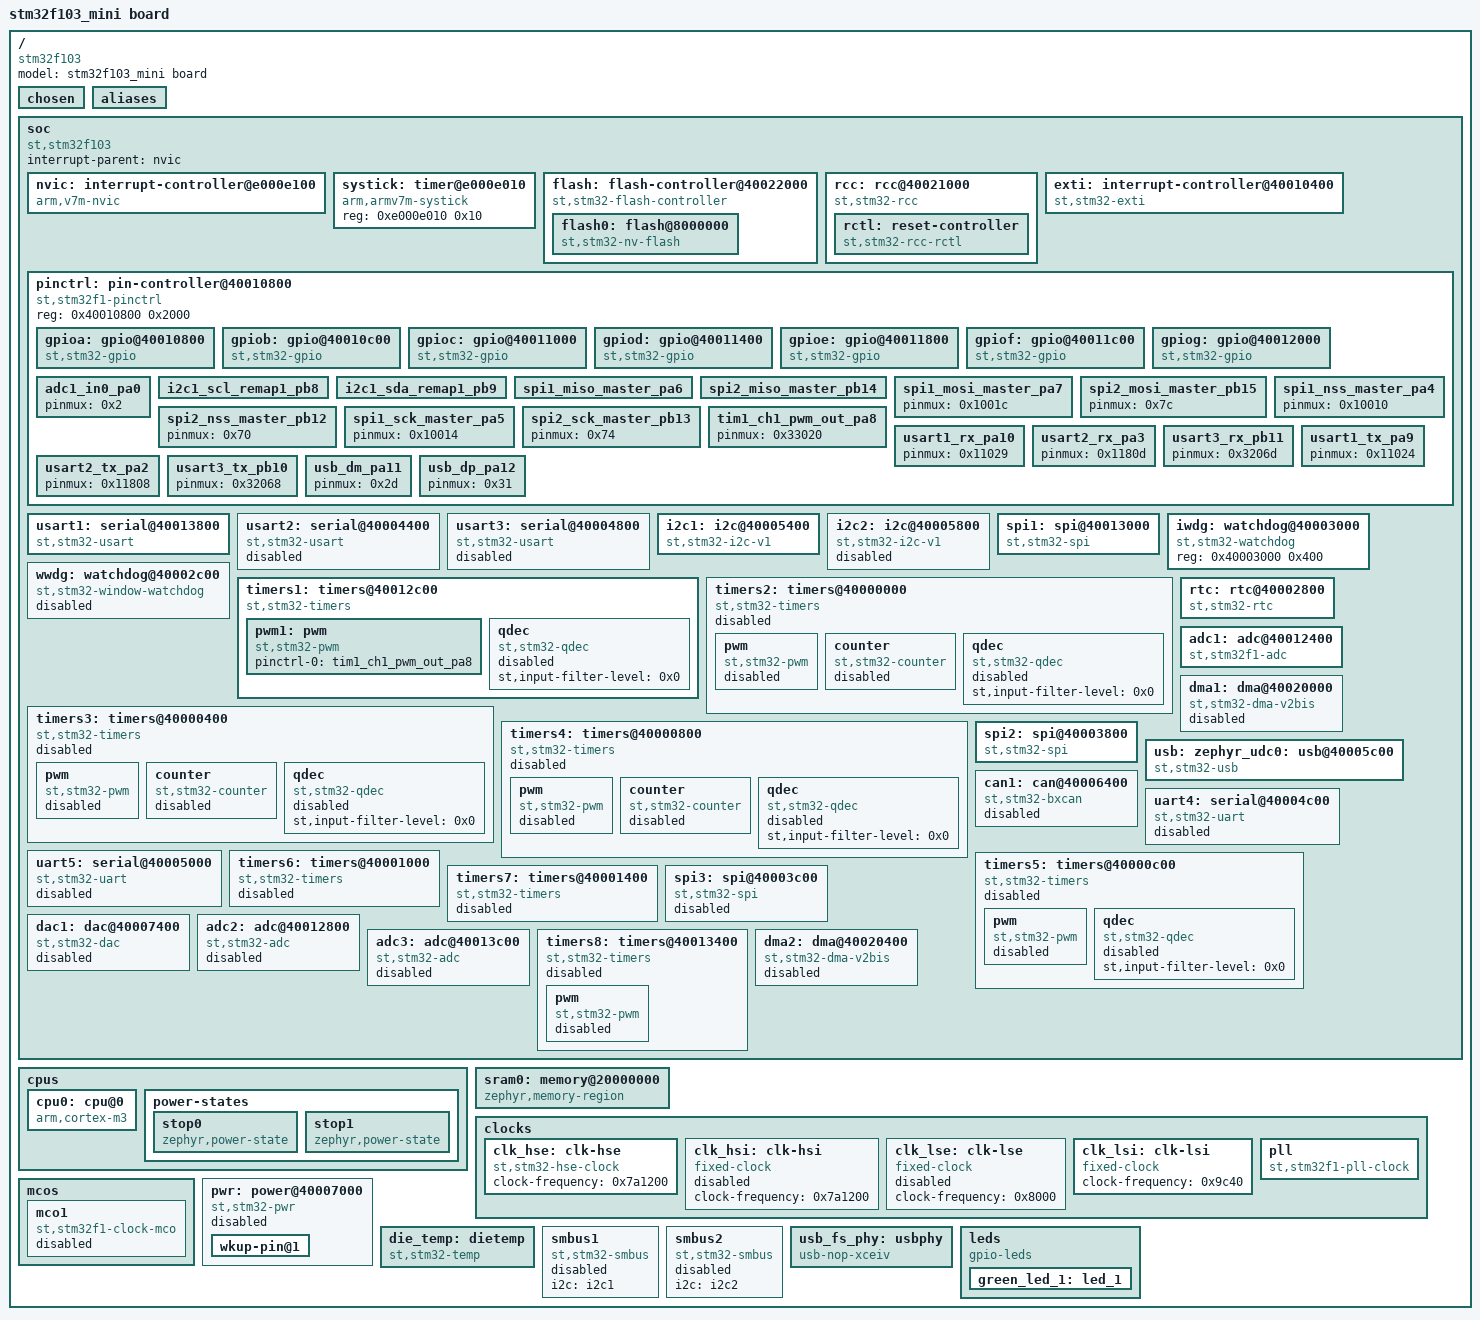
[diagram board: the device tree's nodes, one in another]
/dts-v1/;

/* node '/' defined in zephyr/dts/common/skeleton.dtsi:9 */
/ {
	#address-cells = < 0x1 >;       /* in zephyr/dts/common/skeleton.dtsi:10 */
	#size-cells = < 0x1 >;          /* in zephyr/dts/common/skeleton.dtsi:11 */
	model = "stm32f103_mini board"; /* in zephyr/boards/others/stm32f103_mini/stm32f103_mini.dts:12 */
	compatible = "stm32f103";       /* in zephyr/boards/others/stm32f103_mini/stm32f103_mini.dts:13 */

	/* node '/chosen' defined in zephyr/dts/common/skeleton.dtsi:13 */
	chosen {
		zephyr,flash-controller = &flash;  /* in zephyr/dts/arm/st/f1/stm32f1.dtsi:25 */
		zephyr,cortex-m-idle-timer = &rtc; /* in zephyr/dts/arm/st/f1/stm32f1.dtsi:26 */
		zephyr,console = &usart1;          /* in zephyr/boards/others/stm32f103_mini/stm32f103_mini.dts:16 */
		zephyr,shell-uart = &usart1;       /* in zephyr/boards/others/stm32f103_mini/stm32f103_mini.dts:17 */
		zephyr,sram = &sram0;              /* in zephyr/boards/others/stm32f103_mini/stm32f103_mini.dts:18 */
		zephyr,flash = &flash0;            /* in zephyr/boards/others/stm32f103_mini/stm32f103_mini.dts:19 */
	};

	/* node '/aliases' defined in zephyr/dts/common/skeleton.dtsi:15 */
	aliases {
		led0 = &green_led_1;   /* in zephyr/boards/others/stm32f103_mini/stm32f103_mini.dts:32 */
		watchdog0 = &iwdg;     /* in zephyr/boards/others/stm32f103_mini/stm32f103_mini.dts:33 */
		die-temp0 = &die_temp; /* in zephyr/boards/others/stm32f103_mini/stm32f103_mini.dts:34 */
	};

	/* node '/soc' defined in zephyr/dts/arm/armv7-m.dtsi:6 */
	soc {
		#address-cells = < 0x1 >;     /* in zephyr/dts/arm/armv7-m.dtsi:7 */
		#size-cells = < 0x1 >;        /* in zephyr/dts/arm/armv7-m.dtsi:8 */
		interrupt-parent = < &nvic >; /* in zephyr/dts/arm/armv7-m.dtsi:10 */
		ranges;                       /* in zephyr/dts/arm/armv7-m.dtsi:11 */
		compatible = "st,stm32f103",
		             "st,stm32f1",
		             "simple-bus";    /* in zephyr/dts/arm/st/f1/stm32f103X8.dtsi:15 */

		/* node '/soc/interrupt-controller@e000e100' defined in zephyr/dts/arm/armv7-m.dtsi:13 */
		nvic: interrupt-controller@e000e100 {
			#address-cells = < 0x1 >;            /* in zephyr/dts/arm/armv7-m.dtsi:14 */
			compatible = "arm,v7m-nvic";         /* in zephyr/dts/arm/armv7-m.dtsi:15 */
			reg = < 0xe000e100 0xc00 >;          /* in zephyr/dts/arm/armv7-m.dtsi:16 */
			interrupt-controller;                /* in zephyr/dts/arm/armv7-m.dtsi:17 */
			#interrupt-cells = < 0x2 >;          /* in zephyr/dts/arm/armv7-m.dtsi:18 */
			arm,num-irq-priority-bits = < 0x4 >; /* in zephyr/dts/arm/st/f1/stm32f1.dtsi:461 */
			phandle = < 0x1 >;                   /* in zephyr/dts/arm/armv7-m.dtsi:10 */
		};

		/* node '/soc/timer@e000e010' defined in zephyr/dts/arm/armv7-m.dtsi:21 */
		systick: timer@e000e010 {
			compatible = "arm,armv7m-systick"; /* in zephyr/dts/arm/armv7-m.dtsi:22 */
			reg = < 0xe000e010 0x10 >;         /* in zephyr/dts/arm/armv7-m.dtsi:23 */
		};

		/* node '/soc/flash-controller@40022000' defined in zephyr/dts/arm/st/f1/stm32f1.dtsi:107 */
		flash: flash-controller@40022000 {
			compatible = "st,stm32-flash-controller",
			             "st,stm32f1-flash-controller"; /* in zephyr/dts/arm/st/f1/stm32f1.dtsi:108 */
			reg = < 0x40022000 0x400 >;                 /* in zephyr/dts/arm/st/f1/stm32f1.dtsi:109 */
			interrupts = < 0x3 0x0 >;                   /* in zephyr/dts/arm/st/f1/stm32f1.dtsi:110 */
			clocks = < &rcc 0x14 0x10 >;                /* in zephyr/dts/arm/st/f1/stm32f1.dtsi:111 */
			#address-cells = < 0x1 >;                   /* in zephyr/dts/arm/st/f1/stm32f1.dtsi:113 */
			#size-cells = < 0x1 >;                      /* in zephyr/dts/arm/st/f1/stm32f1.dtsi:114 */

			/* node '/soc/flash-controller@40022000/flash@8000000' defined in zephyr/dts/arm/st/f1/stm32f1.dtsi:116 */
			flash0: flash@8000000 {
				compatible = "st,stm32-nv-flash",
				             "soc-nv-flash";      /* in zephyr/dts/arm/st/f1/stm32f1.dtsi:117 */
				write-block-size = < 0x2 >;       /* in zephyr/dts/arm/st/f1/stm32f1.dtsi:119 */
				max-erase-time = < 0x28 >;        /* in zephyr/dts/arm/st/f1/stm32f1.dtsi:121 */
				reg = < 0x8000000 0x40000 >;      /* in zephyr/dts/arm/st/f1/stm32f103Xc.dtsi:21 */
				erase-block-size = < 0x800 >;     /* in zephyr/dts/arm/st/f1/stm32f103Xc.dtsi:22 */
			};
		};

		/* node '/soc/rcc@40021000' defined in zephyr/dts/arm/st/f1/stm32f1.dtsi:125 */
		rcc: rcc@40021000 {
			compatible = "st,stm32-rcc";     /* in zephyr/dts/arm/st/f1/stm32f1.dtsi:126 */
			#clock-cells = < 0x2 >;          /* in zephyr/dts/arm/st/f1/stm32f1.dtsi:127 */
			reg = < 0x40021000 0x400 >;      /* in zephyr/dts/arm/st/f1/stm32f1.dtsi:128 */
			clocks = < &pll >;               /* in zephyr/boards/others/stm32f103_mini/stm32f103_mini.dts:54 */
			clock-frequency = < 0x44aa200 >; /* in zephyr/boards/others/stm32f103_mini/stm32f103_mini.dts:55 */
			ahb-prescaler = < 0x1 >;         /* in zephyr/boards/others/stm32f103_mini/stm32f103_mini.dts:56 */
			apb1-prescaler = < 0x2 >;        /* in zephyr/boards/others/stm32f103_mini/stm32f103_mini.dts:57 */
			apb2-prescaler = < 0x1 >;        /* in zephyr/boards/others/stm32f103_mini/stm32f103_mini.dts:58 */
			phandle = < 0x2 >;               /* in zephyr/dts/arm/st/f1/stm32f1.dtsi:111 */

			/* node '/soc/rcc@40021000/reset-controller' defined in zephyr/dts/arm/st/f1/stm32f1.dtsi:130 */
			rctl: reset-controller {
				compatible = "st,stm32-rcc-rctl"; /* in zephyr/dts/arm/st/f1/stm32f1.dtsi:131 */
				#reset-cells = < 0x1 >;           /* in zephyr/dts/arm/st/f1/stm32f1.dtsi:132 */
				phandle = < 0x4 >;                /* in zephyr/dts/arm/st/f1/stm32f1.dtsi:202 */
			};
		};

		/* node '/soc/interrupt-controller@40010400' defined in zephyr/dts/arm/st/f1/stm32f1.dtsi:136 */
		exti: interrupt-controller@40010400 {
			compatible = "st,stm32-exti";  /* in zephyr/dts/arm/st/f1/stm32f1.dtsi:137 */
			interrupt-controller;          /* in zephyr/dts/arm/st/f1/stm32f1.dtsi:138 */
			#interrupt-cells = < 0x1 >;    /* in zephyr/dts/arm/st/f1/stm32f1.dtsi:139 */
			#address-cells = < 0x0 >;      /* in zephyr/dts/arm/st/f1/stm32f1.dtsi:140 */
			reg = < 0x40010400 0x400 >;    /* in zephyr/dts/arm/st/f1/stm32f1.dtsi:141 */
			num-lines = < 0x20 >;          /* in zephyr/dts/arm/st/f1/stm32f1.dtsi:142 */
			interrupts = < 0x6 0x0 >,
			             < 0x7 0x0 >,
			             < 0x8 0x0 >,
			             < 0x9 0x0 >,
			             < 0xa 0x0 >,
			             < 0x17 0x0 >,
			             < 0x28 0x0 >;     /* in zephyr/dts/arm/st/f1/stm32f1.dtsi:143 */
			interrupt-names = "line0",
			                  "line1",
			                  "line2",
			                  "line3",
			                  "line4",
			                  "line5-9",
			                  "line10-15"; /* in zephyr/dts/arm/st/f1/stm32f1.dtsi:145 */
			line-ranges = < 0x0 0x1 >,
			              < 0x1 0x1 >,
			              < 0x2 0x1 >,
			              < 0x3 0x1 >,
			              < 0x4 0x1 >,
			              < 0x5 0x5 >,
			              < 0xa 0x6 >;     /* in zephyr/dts/arm/st/f1/stm32f1.dtsi:147 */
		};

		/* node '/soc/pin-controller@40010800' defined in zephyr/dts/arm/st/f1/stm32f1.dtsi:151 */
		pinctrl: pin-controller@40010800 {
			compatible = "st,stm32f1-pinctrl"; /* in zephyr/dts/arm/st/f1/stm32f1.dtsi:152 */
			#address-cells = < 0x1 >;          /* in zephyr/dts/arm/st/f1/stm32f1.dtsi:153 */
			#size-cells = < 0x1 >;             /* in zephyr/dts/arm/st/f1/stm32f1.dtsi:154 */
			reg = < 0x40010800 0x2000 >;       /* in zephyr/dts/arm/st/f1/stm32f103Xc.dtsi:111 */

			/* node '/soc/pin-controller@40010800/gpio@40010800' defined in zephyr/dts/arm/st/f1/stm32f1.dtsi:157 */
			gpioa: gpio@40010800 {
				compatible = "st,stm32-gpio"; /* in zephyr/dts/arm/st/f1/stm32f1.dtsi:158 */
				gpio-controller;              /* in zephyr/dts/arm/st/f1/stm32f1.dtsi:159 */
				#gpio-cells = < 0x2 >;        /* in zephyr/dts/arm/st/f1/stm32f1.dtsi:160 */
				reg = < 0x40010800 0x400 >;   /* in zephyr/dts/arm/st/f1/stm32f1.dtsi:161 */
				clocks = < &rcc 0x18 0x4 >;   /* in zephyr/dts/arm/st/f1/stm32f1.dtsi:162 */
				phandle = < 0x1d >;           /* in zephyr/dts/arm/st/f1/stm32f1.dtsi:430 */
			};

			/* node '/soc/pin-controller@40010800/gpio@40010c00' defined in zephyr/dts/arm/st/f1/stm32f1.dtsi:165 */
			gpiob: gpio@40010c00 {
				compatible = "st,stm32-gpio"; /* in zephyr/dts/arm/st/f1/stm32f1.dtsi:166 */
				gpio-controller;              /* in zephyr/dts/arm/st/f1/stm32f1.dtsi:167 */
				#gpio-cells = < 0x2 >;        /* in zephyr/dts/arm/st/f1/stm32f1.dtsi:168 */
				reg = < 0x40010c00 0x400 >;   /* in zephyr/dts/arm/st/f1/stm32f1.dtsi:169 */
				clocks = < &rcc 0x18 0x8 >;   /* in zephyr/dts/arm/st/f1/stm32f1.dtsi:170 */
			};

			/* node '/soc/pin-controller@40010800/gpio@40011000' defined in zephyr/dts/arm/st/f1/stm32f1.dtsi:173 */
			gpioc: gpio@40011000 {
				compatible = "st,stm32-gpio"; /* in zephyr/dts/arm/st/f1/stm32f1.dtsi:174 */
				gpio-controller;              /* in zephyr/dts/arm/st/f1/stm32f1.dtsi:175 */
				#gpio-cells = < 0x2 >;        /* in zephyr/dts/arm/st/f1/stm32f1.dtsi:176 */
				reg = < 0x40011000 0x400 >;   /* in zephyr/dts/arm/st/f1/stm32f1.dtsi:177 */
				clocks = < &rcc 0x18 0x10 >;  /* in zephyr/dts/arm/st/f1/stm32f1.dtsi:178 */
				phandle = < 0x21 >;           /* in zephyr/boards/others/stm32f103_mini/stm32f103_mini.dts:26 */
			};

			/* node '/soc/pin-controller@40010800/gpio@40011400' defined in zephyr/dts/arm/st/f1/stm32f1.dtsi:181 */
			gpiod: gpio@40011400 {
				compatible = "st,stm32-gpio"; /* in zephyr/dts/arm/st/f1/stm32f1.dtsi:182 */
				gpio-controller;              /* in zephyr/dts/arm/st/f1/stm32f1.dtsi:183 */
				#gpio-cells = < 0x2 >;        /* in zephyr/dts/arm/st/f1/stm32f1.dtsi:184 */
				reg = < 0x40011400 0x400 >;   /* in zephyr/dts/arm/st/f1/stm32f1.dtsi:185 */
				clocks = < &rcc 0x18 0x20 >;  /* in zephyr/dts/arm/st/f1/stm32f1.dtsi:186 */
			};

			/* node '/soc/pin-controller@40010800/gpio@40011800' defined in zephyr/dts/arm/st/f1/stm32f1.dtsi:189 */
			gpioe: gpio@40011800 {
				compatible = "st,stm32-gpio"; /* in zephyr/dts/arm/st/f1/stm32f1.dtsi:190 */
				gpio-controller;              /* in zephyr/dts/arm/st/f1/stm32f1.dtsi:191 */
				#gpio-cells = < 0x2 >;        /* in zephyr/dts/arm/st/f1/stm32f1.dtsi:192 */
				reg = < 0x40011800 0x400 >;   /* in zephyr/dts/arm/st/f1/stm32f1.dtsi:193 */
				clocks = < &rcc 0x18 0x40 >;  /* in zephyr/dts/arm/st/f1/stm32f1.dtsi:194 */
			};

			/* node '/soc/pin-controller@40010800/gpio@40011c00' defined in zephyr/dts/arm/st/f1/stm32f103Xc.dtsi:113 */
			gpiof: gpio@40011c00 {
				compatible = "st,stm32-gpio"; /* in zephyr/dts/arm/st/f1/stm32f103Xc.dtsi:114 */
				gpio-controller;              /* in zephyr/dts/arm/st/f1/stm32f103Xc.dtsi:115 */
				#gpio-cells = < 0x2 >;        /* in zephyr/dts/arm/st/f1/stm32f103Xc.dtsi:116 */
				reg = < 0x40011c00 0x400 >;   /* in zephyr/dts/arm/st/f1/stm32f103Xc.dtsi:117 */
				clocks = < &rcc 0x18 0x80 >;  /* in zephyr/dts/arm/st/f1/stm32f103Xc.dtsi:118 */
			};

			/* node '/soc/pin-controller@40010800/gpio@40012000' defined in zephyr/dts/arm/st/f1/stm32f103Xc.dtsi:121 */
			gpiog: gpio@40012000 {
				compatible = "st,stm32-gpio"; /* in zephyr/dts/arm/st/f1/stm32f103Xc.dtsi:122 */
				gpio-controller;              /* in zephyr/dts/arm/st/f1/stm32f103Xc.dtsi:123 */
				#gpio-cells = < 0x2 >;        /* in zephyr/dts/arm/st/f1/stm32f103Xc.dtsi:124 */
				reg = < 0x40012000 0x400 >;   /* in zephyr/dts/arm/st/f1/stm32f103Xc.dtsi:125 */
				clocks = < &rcc 0x18 0x100 >; /* in zephyr/dts/arm/st/f1/stm32f103Xc.dtsi:126 */
			};

			/* node '/soc/pin-controller@40010800/adc1_in0_pa0' defined in modules/hal/stm32/dts/st/f1/stm32f103r(c-d-e)tx-pinctrl.dtsi:15 */
			adc1_in0_pa0: adc1_in0_pa0 {
				pinmux = < 0x2 >;   /* in modules/hal/stm32/dts/st/f1/stm32f103r(c-d-e)tx-pinctrl.dtsi:16 */
				phandle = < 0x12 >; /* in zephyr/boards/others/stm32f103_mini/stm32f103_mini.dts:130 */
			};

			/* node '/soc/pin-controller@40010800/i2c1_scl_remap1_pb8' defined in modules/hal/stm32/dts/st/f1/stm32f103r(c-d-e)tx-pinctrl.dtsi:418 */
			i2c1_scl_remap1_pb8: i2c1_scl_remap1_pb8 {
				pinmux = < 0x50860 >; /* in modules/hal/stm32/dts/st/f1/stm32f103r(c-d-e)tx-pinctrl.dtsi:419 */
				drive-open-drain;     /* in modules/hal/stm32/dts/st/f1/stm32f103r(c-d-e)tx-pinctrl.dtsi:420 */
				phandle = < 0xb >;    /* in zephyr/boards/others/stm32f103_mini/stm32f103_mini.dts:82 */
			};

			/* node '/soc/pin-controller@40010800/i2c1_sda_remap1_pb9' defined in modules/hal/stm32/dts/st/f1/stm32f103r(c-d-e)tx-pinctrl.dtsi:435 */
			i2c1_sda_remap1_pb9: i2c1_sda_remap1_pb9 {
				pinmux = < 0x50864 >; /* in modules/hal/stm32/dts/st/f1/stm32f103r(c-d-e)tx-pinctrl.dtsi:436 */
				drive-open-drain;     /* in modules/hal/stm32/dts/st/f1/stm32f103r(c-d-e)tx-pinctrl.dtsi:437 */
				phandle = < 0xc >;    /* in zephyr/boards/others/stm32f103_mini/stm32f103_mini.dts:82 */
			};

			/* node '/soc/pin-controller@40010800/spi1_miso_master_pa6' defined in modules/hal/stm32/dts/st/f1/stm32f103r(c-d-e)tx-pinctrl.dtsi:511 */
			spi1_miso_master_pa6: spi1_miso_master_pa6 {
				pinmux = < 0x10019 >; /* in modules/hal/stm32/dts/st/f1/stm32f103r(c-d-e)tx-pinctrl.dtsi:512 */
				bias-pull-down;       /* in modules/hal/stm32/dts/st/f1/stm32f103r(c-d-e)tx-pinctrl.dtsi:513 */
				phandle = < 0xf >;    /* in zephyr/boards/others/stm32f103_mini/stm32f103_mini.dts:89 */
			};

			/* node '/soc/pin-controller@40010800/spi2_miso_master_pb14' defined in modules/hal/stm32/dts/st/f1/stm32f103r(c-d-e)tx-pinctrl.dtsi:521 */
			spi2_miso_master_pb14: spi2_miso_master_pb14 {
				pinmux = < 0x79 >;  /* in modules/hal/stm32/dts/st/f1/stm32f103r(c-d-e)tx-pinctrl.dtsi:522 */
				bias-pull-down;     /* in modules/hal/stm32/dts/st/f1/stm32f103r(c-d-e)tx-pinctrl.dtsi:523 */
				phandle = < 0x15 >; /* in zephyr/boards/others/stm32f103_mini/stm32f103_mini.dts:96 */
			};

			/* node '/soc/pin-controller@40010800/spi1_mosi_master_pa7' defined in modules/hal/stm32/dts/st/f1/stm32f103r(c-d-e)tx-pinctrl.dtsi:533 */
			spi1_mosi_master_pa7: spi1_mosi_master_pa7 {
				pinmux = < 0x1001c >; /* in modules/hal/stm32/dts/st/f1/stm32f103r(c-d-e)tx-pinctrl.dtsi:534 */
				phandle = < 0x10 >;   /* in zephyr/boards/others/stm32f103_mini/stm32f103_mini.dts:89 */
			};

			/* node '/soc/pin-controller@40010800/spi2_mosi_master_pb15' defined in modules/hal/stm32/dts/st/f1/stm32f103r(c-d-e)tx-pinctrl.dtsi:541 */
			spi2_mosi_master_pb15: spi2_mosi_master_pb15 {
				pinmux = < 0x7c >;  /* in modules/hal/stm32/dts/st/f1/stm32f103r(c-d-e)tx-pinctrl.dtsi:542 */
				phandle = < 0x16 >; /* in zephyr/boards/others/stm32f103_mini/stm32f103_mini.dts:96 */
			};

			/* node '/soc/pin-controller@40010800/spi1_nss_master_pa4' defined in modules/hal/stm32/dts/st/f1/stm32f103r(c-d-e)tx-pinctrl.dtsi:551 */
			spi1_nss_master_pa4: spi1_nss_master_pa4 {
				pinmux = < 0x10010 >; /* in modules/hal/stm32/dts/st/f1/stm32f103r(c-d-e)tx-pinctrl.dtsi:552 */
				phandle = < 0xd >;    /* in zephyr/boards/others/stm32f103_mini/stm32f103_mini.dts:89 */
			};

			/* node '/soc/pin-controller@40010800/spi2_nss_master_pb12' defined in modules/hal/stm32/dts/st/f1/stm32f103r(c-d-e)tx-pinctrl.dtsi:559 */
			spi2_nss_master_pb12: spi2_nss_master_pb12 {
				pinmux = < 0x70 >;  /* in modules/hal/stm32/dts/st/f1/stm32f103r(c-d-e)tx-pinctrl.dtsi:560 */
				phandle = < 0x13 >; /* in zephyr/boards/others/stm32f103_mini/stm32f103_mini.dts:96 */
			};

			/* node '/soc/pin-controller@40010800/spi1_sck_master_pa5' defined in modules/hal/stm32/dts/st/f1/stm32f103r(c-d-e)tx-pinctrl.dtsi:569 */
			spi1_sck_master_pa5: spi1_sck_master_pa5 {
				pinmux = < 0x10014 >; /* in modules/hal/stm32/dts/st/f1/stm32f103r(c-d-e)tx-pinctrl.dtsi:570 */
				phandle = < 0xe >;    /* in zephyr/boards/others/stm32f103_mini/stm32f103_mini.dts:89 */
			};

			/* node '/soc/pin-controller@40010800/spi2_sck_master_pb13' defined in modules/hal/stm32/dts/st/f1/stm32f103r(c-d-e)tx-pinctrl.dtsi:577 */
			spi2_sck_master_pb13: spi2_sck_master_pb13 {
				pinmux = < 0x74 >;  /* in modules/hal/stm32/dts/st/f1/stm32f103r(c-d-e)tx-pinctrl.dtsi:578 */
				phandle = < 0x14 >; /* in zephyr/boards/others/stm32f103_mini/stm32f103_mini.dts:96 */
			};

			/* node '/soc/pin-controller@40010800/tim1_ch1_pwm_out_pa8' defined in modules/hal/stm32/dts/st/f1/stm32f103r(c-d-e)tx-pinctrl.dtsi:911 */
			tim1_ch1_pwm_out_pa8: tim1_ch1_pwm_out_pa8 {
				pinmux = < 0x33020 >; /* in modules/hal/stm32/dts/st/f1/stm32f103r(c-d-e)tx-pinctrl.dtsi:912 */
				phandle = < 0x11 >;   /* in zephyr/boards/others/stm32f103_mini/stm32f103_mini.dts:112 */
			};

			/* node '/soc/pin-controller@40010800/usart1_rx_pa10' defined in modules/hal/stm32/dts/st/f1/stm32f103r(c-d-e)tx-pinctrl.dtsi:1181 */
			usart1_rx_pa10: usart1_rx_pa10 {
				pinmux = < 0x11029 >; /* in modules/hal/stm32/dts/st/f1/stm32f103r(c-d-e)tx-pinctrl.dtsi:1182 */
				phandle = < 0x6 >;    /* in zephyr/boards/others/stm32f103_mini/stm32f103_mini.dts:63 */
			};

			/* node '/soc/pin-controller@40010800/usart2_rx_pa3' defined in modules/hal/stm32/dts/st/f1/stm32f103r(c-d-e)tx-pinctrl.dtsi:1189 */
			usart2_rx_pa3: usart2_rx_pa3 {
				pinmux = < 0x1180d >; /* in modules/hal/stm32/dts/st/f1/stm32f103r(c-d-e)tx-pinctrl.dtsi:1190 */
				phandle = < 0x8 >;    /* in zephyr/boards/others/stm32f103_mini/stm32f103_mini.dts:70 */
			};

			/* node '/soc/pin-controller@40010800/usart3_rx_pb11' defined in modules/hal/stm32/dts/st/f1/stm32f103r(c-d-e)tx-pinctrl.dtsi:1193 */
			usart3_rx_pb11: usart3_rx_pb11 {
				pinmux = < 0x3206d >; /* in modules/hal/stm32/dts/st/f1/stm32f103r(c-d-e)tx-pinctrl.dtsi:1194 */
				phandle = < 0xa >;    /* in zephyr/boards/others/stm32f103_mini/stm32f103_mini.dts:76 */
			};

			/* node '/soc/pin-controller@40010800/usart1_tx_pa9' defined in modules/hal/stm32/dts/st/f1/stm32f103r(c-d-e)tx-pinctrl.dtsi:1211 */
			usart1_tx_pa9: usart1_tx_pa9 {
				pinmux = < 0x11024 >; /* in modules/hal/stm32/dts/st/f1/stm32f103r(c-d-e)tx-pinctrl.dtsi:1212 */
				phandle = < 0x5 >;    /* in zephyr/boards/others/stm32f103_mini/stm32f103_mini.dts:63 */
			};

			/* node '/soc/pin-controller@40010800/usart2_tx_pa2' defined in modules/hal/stm32/dts/st/f1/stm32f103r(c-d-e)tx-pinctrl.dtsi:1219 */
			usart2_tx_pa2: usart2_tx_pa2 {
				pinmux = < 0x11808 >; /* in modules/hal/stm32/dts/st/f1/stm32f103r(c-d-e)tx-pinctrl.dtsi:1220 */
				phandle = < 0x7 >;    /* in zephyr/boards/others/stm32f103_mini/stm32f103_mini.dts:70 */
			};

			/* node '/soc/pin-controller@40010800/usart3_tx_pb10' defined in modules/hal/stm32/dts/st/f1/stm32f103r(c-d-e)tx-pinctrl.dtsi:1223 */
			usart3_tx_pb10: usart3_tx_pb10 {
				pinmux = < 0x32068 >; /* in modules/hal/stm32/dts/st/f1/stm32f103r(c-d-e)tx-pinctrl.dtsi:1224 */
				phandle = < 0x9 >;    /* in zephyr/boards/others/stm32f103_mini/stm32f103_mini.dts:76 */
			};

			/* node '/soc/pin-controller@40010800/usb_dm_pa11' defined in modules/hal/stm32/dts/st/f1/stm32f103r(c-d-e)tx-pinctrl.dtsi:1241 */
			usb_dm_pa11: usb_dm_pa11 {
				pinmux = < 0x2d >;  /* in modules/hal/stm32/dts/st/f1/stm32f103r(c-d-e)tx-pinctrl.dtsi:1242 */
				phandle = < 0x18 >; /* in zephyr/boards/others/stm32f103_mini/stm32f103_mini.dts:118 */
			};

			/* node '/soc/pin-controller@40010800/usb_dp_pa12' defined in modules/hal/stm32/dts/st/f1/stm32f103r(c-d-e)tx-pinctrl.dtsi:1245 */
			usb_dp_pa12: usb_dp_pa12 {
				pinmux = < 0x31 >;  /* in modules/hal/stm32/dts/st/f1/stm32f103r(c-d-e)tx-pinctrl.dtsi:1246 */
				phandle = < 0x19 >; /* in zephyr/boards/others/stm32f103_mini/stm32f103_mini.dts:118 */
			};
		};

		/* node '/soc/serial@40013800' defined in zephyr/dts/arm/st/f1/stm32f1.dtsi:198 */
		usart1: serial@40013800 {
			compatible = "st,stm32-usart",
			             "st,stm32-uart";                   /* in zephyr/dts/arm/st/f1/stm32f1.dtsi:199 */
			reg = < 0x40013800 0x400 >;                     /* in zephyr/dts/arm/st/f1/stm32f1.dtsi:200 */
			clocks = < &rcc 0x18 0x4000 >;                  /* in zephyr/dts/arm/st/f1/stm32f1.dtsi:201 */
			resets = < &rctl 0x18e >;                       /* in zephyr/dts/arm/st/f1/stm32f1.dtsi:202 */
			interrupts = < 0x25 0x0 >;                      /* in zephyr/dts/arm/st/f1/stm32f1.dtsi:203 */
			pinctrl-0 = < &usart1_tx_pa9 &usart1_rx_pa10 >; /* in zephyr/boards/others/stm32f103_mini/stm32f103_mini.dts:63 */
			pinctrl-names = "default";                      /* in zephyr/boards/others/stm32f103_mini/stm32f103_mini.dts:64 */
			current-speed = < 0x1c200 >;                    /* in zephyr/boards/others/stm32f103_mini/stm32f103_mini.dts:65 */
			status = "okay";                                /* in zephyr/boards/others/stm32f103_mini/stm32f103_mini.dts:66 */
		};

		/* node '/soc/serial@40004400' defined in zephyr/dts/arm/st/f1/stm32f1.dtsi:207 */
		usart2: serial@40004400 {
			compatible = "st,stm32-usart",
			             "st,stm32-uart";                  /* in zephyr/dts/arm/st/f1/stm32f1.dtsi:208 */
			reg = < 0x40004400 0x400 >;                    /* in zephyr/dts/arm/st/f1/stm32f1.dtsi:209 */
			clocks = < &rcc 0x1c 0x20000 >;                /* in zephyr/dts/arm/st/f1/stm32f1.dtsi:210 */
			resets = < &rctl 0x211 >;                      /* in zephyr/dts/arm/st/f1/stm32f1.dtsi:211 */
			interrupts = < 0x26 0x0 >;                     /* in zephyr/dts/arm/st/f1/stm32f1.dtsi:212 */
			status = "disabled";                           /* in zephyr/dts/arm/st/f1/stm32f1.dtsi:213 */
			pinctrl-0 = < &usart2_tx_pa2 &usart2_rx_pa3 >; /* in zephyr/boards/others/stm32f103_mini/stm32f103_mini.dts:70 */
			pinctrl-names = "default";                     /* in zephyr/boards/others/stm32f103_mini/stm32f103_mini.dts:71 */
			current-speed = < 0x1c200 >;                   /* in zephyr/boards/others/stm32f103_mini/stm32f103_mini.dts:72 */
		};

		/* node '/soc/serial@40004800' defined in zephyr/dts/arm/st/f1/stm32f1.dtsi:216 */
		usart3: serial@40004800 {
			compatible = "st,stm32-usart",
			             "st,stm32-uart";                    /* in zephyr/dts/arm/st/f1/stm32f1.dtsi:217 */
			reg = < 0x40004800 0x400 >;                      /* in zephyr/dts/arm/st/f1/stm32f1.dtsi:218 */
			clocks = < &rcc 0x1c 0x40000 >;                  /* in zephyr/dts/arm/st/f1/stm32f1.dtsi:219 */
			resets = < &rctl 0x212 >;                        /* in zephyr/dts/arm/st/f1/stm32f1.dtsi:220 */
			interrupts = < 0x27 0x0 >;                       /* in zephyr/dts/arm/st/f1/stm32f1.dtsi:221 */
			status = "disabled";                             /* in zephyr/dts/arm/st/f1/stm32f1.dtsi:222 */
			pinctrl-0 = < &usart3_tx_pb10 &usart3_rx_pb11 >; /* in zephyr/boards/others/stm32f103_mini/stm32f103_mini.dts:76 */
			pinctrl-names = "default";                       /* in zephyr/boards/others/stm32f103_mini/stm32f103_mini.dts:77 */
			current-speed = < 0x1c200 >;                     /* in zephyr/boards/others/stm32f103_mini/stm32f103_mini.dts:78 */
		};

		/* node '/soc/i2c@40005400' defined in zephyr/dts/arm/st/f1/stm32f1.dtsi:225 */
		i2c1: i2c@40005400 {
			compatible = "st,stm32-i2c-v1";                            /* in zephyr/dts/arm/st/f1/stm32f1.dtsi:226 */
			#address-cells = < 0x1 >;                                  /* in zephyr/dts/arm/st/f1/stm32f1.dtsi:228 */
			#size-cells = < 0x0 >;                                     /* in zephyr/dts/arm/st/f1/stm32f1.dtsi:229 */
			reg = < 0x40005400 0x400 >;                                /* in zephyr/dts/arm/st/f1/stm32f1.dtsi:230 */
			clocks = < &rcc 0x1c 0x200000 >;                           /* in zephyr/dts/arm/st/f1/stm32f1.dtsi:231 */
			interrupts = < 0x1f 0x0 >,
			             < 0x20 0x0 >;                                 /* in zephyr/dts/arm/st/f1/stm32f1.dtsi:232 */
			interrupt-names = "event",
			                  "error";                                 /* in zephyr/dts/arm/st/f1/stm32f1.dtsi:233 */
			pinctrl-0 = < &i2c1_scl_remap1_pb8 &i2c1_sda_remap1_pb9 >; /* in zephyr/boards/others/stm32f103_mini/stm32f103_mini.dts:82 */
			pinctrl-names = "default";                                 /* in zephyr/boards/others/stm32f103_mini/stm32f103_mini.dts:83 */
			status = "okay";                                           /* in zephyr/boards/others/stm32f103_mini/stm32f103_mini.dts:84 */
			clock-frequency = < 0x61a80 >;                             /* in zephyr/boards/others/stm32f103_mini/stm32f103_mini.dts:85 */
			phandle = < 0x1f >;                                        /* in zephyr/dts/arm/st/f1/stm32f1.dtsi:447 */
		};

		/* node '/soc/i2c@40005800' defined in zephyr/dts/arm/st/f1/stm32f1.dtsi:237 */
		i2c2: i2c@40005800 {
			compatible = "st,stm32-i2c-v1";  /* in zephyr/dts/arm/st/f1/stm32f1.dtsi:238 */
			clock-frequency = < 0x186a0 >;   /* in zephyr/dts/arm/st/f1/stm32f1.dtsi:239 */
			#address-cells = < 0x1 >;        /* in zephyr/dts/arm/st/f1/stm32f1.dtsi:240 */
			#size-cells = < 0x0 >;           /* in zephyr/dts/arm/st/f1/stm32f1.dtsi:241 */
			reg = < 0x40005800 0x400 >;      /* in zephyr/dts/arm/st/f1/stm32f1.dtsi:242 */
			clocks = < &rcc 0x1c 0x400000 >; /* in zephyr/dts/arm/st/f1/stm32f1.dtsi:243 */
			interrupts = < 0x21 0x0 >,
			             < 0x22 0x0 >;       /* in zephyr/dts/arm/st/f1/stm32f1.dtsi:244 */
			interrupt-names = "event",
			                  "error";       /* in zephyr/dts/arm/st/f1/stm32f1.dtsi:245 */
			status = "disabled";             /* in zephyr/dts/arm/st/f1/stm32f1.dtsi:246 */
			phandle = < 0x20 >;              /* in zephyr/dts/arm/st/f1/stm32f1.dtsi:455 */
		};

		/* node '/soc/spi@40013000' defined in zephyr/dts/arm/st/f1/stm32f1.dtsi:249 */
		spi1: spi@40013000 {
			compatible = "st,stm32-spi";                                                                           /* in zephyr/dts/arm/st/f1/stm32f1.dtsi:250 */
			#address-cells = < 0x1 >;                                                                              /* in zephyr/dts/arm/st/f1/stm32f1.dtsi:251 */
			#size-cells = < 0x0 >;                                                                                 /* in zephyr/dts/arm/st/f1/stm32f1.dtsi:252 */
			reg = < 0x40013000 0x400 >;                                                                            /* in zephyr/dts/arm/st/f1/stm32f1.dtsi:253 */
			clocks = < &rcc 0x18 0x1000 >;                                                                         /* in zephyr/dts/arm/st/f1/stm32f1.dtsi:254 */
			interrupts = < 0x23 0x5 >;                                                                             /* in zephyr/dts/arm/st/f1/stm32f1.dtsi:255 */
			pinctrl-0 = < &spi1_nss_master_pa4 &spi1_sck_master_pa5 &spi1_miso_master_pa6 &spi1_mosi_master_pa7 >; /* in zephyr/boards/others/stm32f103_mini/stm32f103_mini.dts:89 */
			pinctrl-names = "default";                                                                             /* in zephyr/boards/others/stm32f103_mini/stm32f103_mini.dts:91 */
			status = "okay";                                                                                       /* in zephyr/boards/others/stm32f103_mini/stm32f103_mini.dts:92 */
		};

		/* node '/soc/watchdog@40003000' defined in zephyr/dts/arm/st/f1/stm32f1.dtsi:259 */
		iwdg: watchdog@40003000 {
			compatible = "st,stm32-watchdog"; /* in zephyr/dts/arm/st/f1/stm32f1.dtsi:260 */
			reg = < 0x40003000 0x400 >;       /* in zephyr/dts/arm/st/f1/stm32f1.dtsi:261 */
			status = "okay";                  /* in zephyr/boards/others/stm32f103_mini/stm32f103_mini.dts:103 */
		};

		/* node '/soc/watchdog@40002c00' defined in zephyr/dts/arm/st/f1/stm32f1.dtsi:265 */
		wwdg: watchdog@40002c00 {
			compatible = "st,stm32-window-watchdog"; /* in zephyr/dts/arm/st/f1/stm32f1.dtsi:266 */
			reg = < 0x40002c00 0x400 >;              /* in zephyr/dts/arm/st/f1/stm32f1.dtsi:267 */
			clocks = < &rcc 0x1c 0x800 >;            /* in zephyr/dts/arm/st/f1/stm32f1.dtsi:268 */
			interrupts = < 0x0 0x7 >;                /* in zephyr/dts/arm/st/f1/stm32f1.dtsi:269 */
			status = "disabled";                     /* in zephyr/dts/arm/st/f1/stm32f1.dtsi:270 */
		};

		/* node '/soc/timers@40012c00' defined in zephyr/dts/arm/st/f1/stm32f1.dtsi:273 */
		timers1: timers@40012c00 {
			compatible = "st,stm32-timers"; /* in zephyr/dts/arm/st/f1/stm32f1.dtsi:274 */
			reg = < 0x40012c00 0x400 >;     /* in zephyr/dts/arm/st/f1/stm32f1.dtsi:275 */
			clocks = < &rcc 0x18 0x800 >,
			         < &rcc 0x9 0xff >;     /* in zephyr/dts/arm/st/f1/stm32f1.dtsi:276 */
			resets = < &rctl 0x18b >;       /* in zephyr/dts/arm/st/f1/stm32f1.dtsi:278 */
			interrupts = < 0x18 0x0 >,
			             < 0x19 0x0 >,
			             < 0x1a 0x0 >,
			             < 0x1b 0x0 >;      /* in zephyr/dts/arm/st/f1/stm32f1.dtsi:279 */
			interrupt-names = "brk",
			                  "up",
			                  "trgcom",
			                  "cc";         /* in zephyr/dts/arm/st/f1/stm32f1.dtsi:280 */
			st,prescaler = < 0x2710 >;      /* in zephyr/boards/others/stm32f103_mini/stm32f103_mini.dts:107 */
			status = "okay";                /* in zephyr/boards/others/stm32f103_mini/stm32f103_mini.dts:108 */

			/* node '/soc/timers@40012c00/pwm' defined in zephyr/dts/arm/st/f1/stm32f1.dtsi:284 */
			pwm1: pwm {
				compatible = "st,stm32-pwm";           /* in zephyr/dts/arm/st/f1/stm32f1.dtsi:285 */
				#pwm-cells = < 0x3 >;                  /* in zephyr/dts/arm/st/f1/stm32f1.dtsi:287 */
				status = "okay";                       /* in zephyr/boards/others/stm32f103_mini/stm32f103_mini.dts:111 */
				pinctrl-0 = < &tim1_ch1_pwm_out_pa8 >; /* in zephyr/boards/others/stm32f103_mini/stm32f103_mini.dts:112 */
				pinctrl-names = "default";             /* in zephyr/boards/others/stm32f103_mini/stm32f103_mini.dts:113 */
			};

			/* node '/soc/timers@40012c00/qdec' defined in zephyr/dts/arm/st/f1/stm32f1.dtsi:290 */
			qdec {
				compatible = "st,stm32-qdec";    /* in zephyr/dts/arm/st/f1/stm32f1.dtsi:291 */
				st,input-filter-level = < 0x0 >; /* in zephyr/dts/arm/st/f1/stm32f1.dtsi:292 */
				status = "disabled";             /* in zephyr/dts/arm/st/f1/stm32f1.dtsi:293 */
			};
		};

		/* node '/soc/timers@40000000' defined in zephyr/dts/arm/st/f1/stm32f1.dtsi:297 */
		timers2: timers@40000000 {
			compatible = "st,stm32-timers"; /* in zephyr/dts/arm/st/f1/stm32f1.dtsi:298 */
			reg = < 0x40000000 0x400 >;     /* in zephyr/dts/arm/st/f1/stm32f1.dtsi:299 */
			clocks = < &rcc 0x1c 0x1 >,
			         < &rcc 0x8 0xff >;     /* in zephyr/dts/arm/st/f1/stm32f1.dtsi:300 */
			resets = < &rctl 0x200 >;       /* in zephyr/dts/arm/st/f1/stm32f1.dtsi:302 */
			interrupts = < 0x1c 0x0 >;      /* in zephyr/dts/arm/st/f1/stm32f1.dtsi:303 */
			interrupt-names = "global";     /* in zephyr/dts/arm/st/f1/stm32f1.dtsi:304 */
			st,prescaler = < 0x0 >;         /* in zephyr/dts/arm/st/f1/stm32f1.dtsi:305 */
			status = "disabled";            /* in zephyr/dts/arm/st/f1/stm32f1.dtsi:306 */

			/* node '/soc/timers@40000000/pwm' defined in zephyr/dts/arm/st/f1/stm32f1.dtsi:308 */
			pwm {
				compatible = "st,stm32-pwm"; /* in zephyr/dts/arm/st/f1/stm32f1.dtsi:309 */
				status = "disabled";         /* in zephyr/dts/arm/st/f1/stm32f1.dtsi:310 */
				#pwm-cells = < 0x3 >;        /* in zephyr/dts/arm/st/f1/stm32f1.dtsi:311 */
			};

			/* node '/soc/timers@40000000/counter' defined in zephyr/dts/arm/st/f1/stm32f1.dtsi:314 */
			counter {
				compatible = "st,stm32-counter"; /* in zephyr/dts/arm/st/f1/stm32f1.dtsi:315 */
				status = "disabled";             /* in zephyr/dts/arm/st/f1/stm32f1.dtsi:316 */
			};

			/* node '/soc/timers@40000000/qdec' defined in zephyr/dts/arm/st/f1/stm32f1.dtsi:319 */
			qdec {
				compatible = "st,stm32-qdec";    /* in zephyr/dts/arm/st/f1/stm32f1.dtsi:320 */
				st,input-filter-level = < 0x0 >; /* in zephyr/dts/arm/st/f1/stm32f1.dtsi:321 */
				status = "disabled";             /* in zephyr/dts/arm/st/f1/stm32f1.dtsi:322 */
			};
		};

		/* node '/soc/timers@40000400' defined in zephyr/dts/arm/st/f1/stm32f1.dtsi:326 */
		timers3: timers@40000400 {
			compatible = "st,stm32-timers"; /* in zephyr/dts/arm/st/f1/stm32f1.dtsi:327 */
			reg = < 0x40000400 0x400 >;     /* in zephyr/dts/arm/st/f1/stm32f1.dtsi:328 */
			clocks = < &rcc 0x1c 0x2 >,
			         < &rcc 0x8 0xff >;     /* in zephyr/dts/arm/st/f1/stm32f1.dtsi:329 */
			resets = < &rctl 0x201 >;       /* in zephyr/dts/arm/st/f1/stm32f1.dtsi:331 */
			interrupts = < 0x1d 0x0 >;      /* in zephyr/dts/arm/st/f1/stm32f1.dtsi:332 */
			interrupt-names = "global";     /* in zephyr/dts/arm/st/f1/stm32f1.dtsi:333 */
			st,prescaler = < 0x0 >;         /* in zephyr/dts/arm/st/f1/stm32f1.dtsi:334 */
			status = "disabled";            /* in zephyr/dts/arm/st/f1/stm32f1.dtsi:335 */

			/* node '/soc/timers@40000400/pwm' defined in zephyr/dts/arm/st/f1/stm32f1.dtsi:337 */
			pwm {
				compatible = "st,stm32-pwm"; /* in zephyr/dts/arm/st/f1/stm32f1.dtsi:338 */
				status = "disabled";         /* in zephyr/dts/arm/st/f1/stm32f1.dtsi:339 */
				#pwm-cells = < 0x3 >;        /* in zephyr/dts/arm/st/f1/stm32f1.dtsi:340 */
			};

			/* node '/soc/timers@40000400/counter' defined in zephyr/dts/arm/st/f1/stm32f1.dtsi:343 */
			counter {
				compatible = "st,stm32-counter"; /* in zephyr/dts/arm/st/f1/stm32f1.dtsi:344 */
				status = "disabled";             /* in zephyr/dts/arm/st/f1/stm32f1.dtsi:345 */
			};

			/* node '/soc/timers@40000400/qdec' defined in zephyr/dts/arm/st/f1/stm32f1.dtsi:348 */
			qdec {
				compatible = "st,stm32-qdec";    /* in zephyr/dts/arm/st/f1/stm32f1.dtsi:349 */
				st,input-filter-level = < 0x0 >; /* in zephyr/dts/arm/st/f1/stm32f1.dtsi:350 */
				status = "disabled";             /* in zephyr/dts/arm/st/f1/stm32f1.dtsi:351 */
			};
		};

		/* node '/soc/timers@40000800' defined in zephyr/dts/arm/st/f1/stm32f1.dtsi:355 */
		timers4: timers@40000800 {
			compatible = "st,stm32-timers"; /* in zephyr/dts/arm/st/f1/stm32f1.dtsi:356 */
			reg = < 0x40000800 0x400 >;     /* in zephyr/dts/arm/st/f1/stm32f1.dtsi:357 */
			clocks = < &rcc 0x1c 0x4 >,
			         < &rcc 0x8 0xff >;     /* in zephyr/dts/arm/st/f1/stm32f1.dtsi:358 */
			resets = < &rctl 0x202 >;       /* in zephyr/dts/arm/st/f1/stm32f1.dtsi:360 */
			interrupts = < 0x1e 0x0 >;      /* in zephyr/dts/arm/st/f1/stm32f1.dtsi:361 */
			interrupt-names = "global";     /* in zephyr/dts/arm/st/f1/stm32f1.dtsi:362 */
			st,prescaler = < 0x0 >;         /* in zephyr/dts/arm/st/f1/stm32f1.dtsi:363 */
			status = "disabled";            /* in zephyr/dts/arm/st/f1/stm32f1.dtsi:364 */

			/* node '/soc/timers@40000800/pwm' defined in zephyr/dts/arm/st/f1/stm32f1.dtsi:366 */
			pwm {
				compatible = "st,stm32-pwm"; /* in zephyr/dts/arm/st/f1/stm32f1.dtsi:367 */
				status = "disabled";         /* in zephyr/dts/arm/st/f1/stm32f1.dtsi:368 */
				#pwm-cells = < 0x3 >;        /* in zephyr/dts/arm/st/f1/stm32f1.dtsi:369 */
			};

			/* node '/soc/timers@40000800/counter' defined in zephyr/dts/arm/st/f1/stm32f1.dtsi:372 */
			counter {
				compatible = "st,stm32-counter"; /* in zephyr/dts/arm/st/f1/stm32f1.dtsi:373 */
				status = "disabled";             /* in zephyr/dts/arm/st/f1/stm32f1.dtsi:374 */
			};

			/* node '/soc/timers@40000800/qdec' defined in zephyr/dts/arm/st/f1/stm32f1.dtsi:377 */
			qdec {
				compatible = "st,stm32-qdec";    /* in zephyr/dts/arm/st/f1/stm32f1.dtsi:378 */
				st,input-filter-level = < 0x0 >; /* in zephyr/dts/arm/st/f1/stm32f1.dtsi:379 */
				status = "disabled";             /* in zephyr/dts/arm/st/f1/stm32f1.dtsi:380 */
			};
		};

		/* node '/soc/rtc@40002800' defined in zephyr/dts/arm/st/f1/stm32f1.dtsi:384 */
		rtc: rtc@40002800 {
			compatible = "st,stm32-rtc";       /* in zephyr/dts/arm/st/f1/stm32f1.dtsi:385 */
			reg = < 0x40002800 0x400 >;        /* in zephyr/dts/arm/st/f1/stm32f1.dtsi:386 */
			interrupts = < 0x29 0x0 >;         /* in zephyr/dts/arm/st/f1/stm32f1.dtsi:387 */
			prescaler = < 0x8000 >;            /* in zephyr/dts/arm/st/f1/stm32f1.dtsi:389 */
			clocks = < &rcc 0x1c 0x10000000 >,
			         < &rcc 0x3 0x2280020 >;   /* in zephyr/boards/others/stm32f103_mini/stm32f103_mini.dts:124 */
			status = "okay";                   /* in zephyr/boards/others/stm32f103_mini/stm32f103_mini.dts:126 */
		};

		/* node '/soc/adc@40012400' defined in zephyr/dts/arm/st/f1/stm32f1.dtsi:393 */
		adc1: adc@40012400 {
			compatible = "st,stm32f1-adc",
			             "st,stm32-adc";                               /* in zephyr/dts/arm/st/f1/stm32f1.dtsi:394 */
			reg = < 0x40012400 0x400 >;                                /* in zephyr/dts/arm/st/f1/stm32f1.dtsi:395 */
			clocks = < &rcc 0x18 0x200 >;                              /* in zephyr/dts/arm/st/f1/stm32f1.dtsi:396 */
			clock-names = "adcx";                                      /* in zephyr/dts/arm/st/f1/stm32f1.dtsi:397 */
			interrupts = < 0x12 0x0 >;                                 /* in zephyr/dts/arm/st/f1/stm32f1.dtsi:398 */
			#io-channel-cells = < 0x1 >;                               /* in zephyr/dts/arm/st/f1/stm32f1.dtsi:399 */
			resolutions = < 0x6000ff >;                                /* in zephyr/dts/arm/st/f1/stm32f1.dtsi:400 */
			sampling-times = < 0x2 0x8 0xe 0x1d 0x2a 0x38 0x48 0xf0 >; /* in zephyr/dts/arm/st/f1/stm32f1.dtsi:401 */
			st,adc-sequencer = "programmable";                         /* in zephyr/dts/arm/st/f1/stm32f1.dtsi:402 */
			st,adc-oversampler = "none";                               /* in zephyr/dts/arm/st/f1/stm32f1.dtsi:403 */
			st,adc-internal-regulator = "none";                        /* in zephyr/dts/arm/st/f1/stm32f1.dtsi:404 */
			pinctrl-0 = < &adc1_in0_pa0 >;                             /* in zephyr/boards/others/stm32f103_mini/stm32f103_mini.dts:130 */
			pinctrl-names = "default";                                 /* in zephyr/boards/others/stm32f103_mini/stm32f103_mini.dts:131 */
			status = "okay";                                           /* in zephyr/boards/others/stm32f103_mini/stm32f103_mini.dts:132 */
			phandle = < 0x1e >;                                        /* in zephyr/dts/arm/st/f1/stm32f1.dtsi:436 */
		};

		/* node '/soc/dma@40020000' defined in zephyr/dts/arm/st/f1/stm32f1.dtsi:408 */
		dma1: dma@40020000 {
			compatible = "st,stm32-dma-v2bis";                                          /* in zephyr/dts/arm/st/f1/stm32f1.dtsi:409 */
			#dma-cells = < 0x2 >;                                                       /* in zephyr/dts/arm/st/f1/stm32f1.dtsi:410 */
			reg = < 0x40020000 0x400 >;                                                 /* in zephyr/dts/arm/st/f1/stm32f1.dtsi:411 */
			clocks = < &rcc 0x14 0x1 >;                                                 /* in zephyr/dts/arm/st/f1/stm32f1.dtsi:412 */
			interrupts = < 0xb 0x0 0xc 0x0 0xd 0x0 0xe 0x0 0xf 0x0 0x10 0x0 0x11 0x0 >; /* in zephyr/dts/arm/st/f1/stm32f1.dtsi:413 */
			status = "disabled";                                                        /* in zephyr/dts/arm/st/f1/stm32f1.dtsi:414 */
		};

		/* node '/soc/spi@40003800' defined in zephyr/dts/arm/st/f1/stm32f103X8.dtsi:27 */
		spi2: spi@40003800 {
			compatible = "st,stm32-spi";                                                                               /* in zephyr/dts/arm/st/f1/stm32f103X8.dtsi:28 */
			#address-cells = < 0x1 >;                                                                                  /* in zephyr/dts/arm/st/f1/stm32f103X8.dtsi:29 */
			#size-cells = < 0x0 >;                                                                                     /* in zephyr/dts/arm/st/f1/stm32f103X8.dtsi:30 */
			reg = < 0x40003800 0x400 >;                                                                                /* in zephyr/dts/arm/st/f1/stm32f103X8.dtsi:31 */
			clocks = < &rcc 0x1c 0x4000 >;                                                                             /* in zephyr/dts/arm/st/f1/stm32f103X8.dtsi:32 */
			interrupts = < 0x24 0x5 >;                                                                                 /* in zephyr/dts/arm/st/f1/stm32f103X8.dtsi:33 */
			pinctrl-0 = < &spi2_nss_master_pb12 &spi2_sck_master_pb13 &spi2_miso_master_pb14 &spi2_mosi_master_pb15 >; /* in zephyr/boards/others/stm32f103_mini/stm32f103_mini.dts:96 */
			pinctrl-names = "default";                                                                                 /* in zephyr/boards/others/stm32f103_mini/stm32f103_mini.dts:98 */
			status = "okay";                                                                                           /* in zephyr/boards/others/stm32f103_mini/stm32f103_mini.dts:99 */
		};

		/* node '/soc/usb@40005c00' defined in zephyr/dts/arm/st/f1/stm32f103X8.dtsi:37 */
		usb: zephyr_udc0: usb@40005c00 {
			compatible = "st,stm32-usb";               /* in zephyr/dts/arm/st/f1/stm32f103X8.dtsi:38 */
			reg = < 0x40005c00 0x400 >;                /* in zephyr/dts/arm/st/f1/stm32f103X8.dtsi:39 */
			interrupts = < 0x14 0x0 >;                 /* in zephyr/dts/arm/st/f1/stm32f103X8.dtsi:40 */
			interrupt-names = "usb";                   /* in zephyr/dts/arm/st/f1/stm32f103X8.dtsi:41 */
			num-bidir-endpoints = < 0x8 >;             /* in zephyr/dts/arm/st/f1/stm32f103X8.dtsi:42 */
			ram-size = < 0x200 >;                      /* in zephyr/dts/arm/st/f1/stm32f103X8.dtsi:43 */
			maximum-speed = "full-speed";              /* in zephyr/dts/arm/st/f1/stm32f103X8.dtsi:44 */
			clocks = < &rcc 0x1c 0x800000 >;           /* in zephyr/dts/arm/st/f1/stm32f103X8.dtsi:46 */
			phys = < &usb_fs_phy >;                    /* in zephyr/dts/arm/st/f1/stm32f103X8.dtsi:47 */
			pinctrl-0 = < &usb_dm_pa11 &usb_dp_pa12 >; /* in zephyr/boards/others/stm32f103_mini/stm32f103_mini.dts:118 */
			pinctrl-names = "default";                 /* in zephyr/boards/others/stm32f103_mini/stm32f103_mini.dts:119 */
			status = "okay";                           /* in zephyr/boards/others/stm32f103_mini/stm32f103_mini.dts:120 */
		};

		/* node '/soc/can@40006400' defined in zephyr/dts/arm/st/f1/stm32f103X8.dtsi:50 */
		can1: can@40006400 {
			compatible = "st,stm32-bxcan";    /* in zephyr/dts/arm/st/f1/stm32f103X8.dtsi:51 */
			reg = < 0x40006400 0x400 >;       /* in zephyr/dts/arm/st/f1/stm32f103X8.dtsi:52 */
			interrupts = < 0x13 0x0 >,
			             < 0x14 0x0 >,
			             < 0x15 0x0 >,
			             < 0x16 0x0 >;        /* in zephyr/dts/arm/st/f1/stm32f103X8.dtsi:53 */
			interrupt-names = "TX",
			                  "RX0",
			                  "RX1",
			                  "SCE";          /* in zephyr/dts/arm/st/f1/stm32f103X8.dtsi:54 */
			clocks = < &rcc 0x1c 0x2000000 >; /* in zephyr/dts/arm/st/f1/stm32f103X8.dtsi:55 */
			status = "disabled";              /* in zephyr/dts/arm/st/f1/stm32f103X8.dtsi:56 */
		};

		/* node '/soc/serial@40004c00' defined in zephyr/dts/arm/st/f1/stm32f103Xc.dtsi:26 */
		uart4: serial@40004c00 {
			compatible = "st,stm32-uart";   /* in zephyr/dts/arm/st/f1/stm32f103Xc.dtsi:27 */
			reg = < 0x40004c00 0x400 >;     /* in zephyr/dts/arm/st/f1/stm32f103Xc.dtsi:28 */
			clocks = < &rcc 0x1c 0x80000 >; /* in zephyr/dts/arm/st/f1/stm32f103Xc.dtsi:29 */
			resets = < &rctl 0x213 >;       /* in zephyr/dts/arm/st/f1/stm32f103Xc.dtsi:30 */
			interrupts = < 0x34 0x0 >;      /* in zephyr/dts/arm/st/f1/stm32f103Xc.dtsi:31 */
			status = "disabled";            /* in zephyr/dts/arm/st/f1/stm32f103Xc.dtsi:32 */
		};

		/* node '/soc/serial@40005000' defined in zephyr/dts/arm/st/f1/stm32f103Xc.dtsi:35 */
		uart5: serial@40005000 {
			compatible = "st,stm32-uart";    /* in zephyr/dts/arm/st/f1/stm32f103Xc.dtsi:36 */
			reg = < 0x40005000 0x400 >;      /* in zephyr/dts/arm/st/f1/stm32f103Xc.dtsi:37 */
			clocks = < &rcc 0x1c 0x100000 >; /* in zephyr/dts/arm/st/f1/stm32f103Xc.dtsi:38 */
			resets = < &rctl 0x214 >;        /* in zephyr/dts/arm/st/f1/stm32f103Xc.dtsi:39 */
			interrupts = < 0x35 0x0 >;       /* in zephyr/dts/arm/st/f1/stm32f103Xc.dtsi:40 */
			status = "disabled";             /* in zephyr/dts/arm/st/f1/stm32f103Xc.dtsi:41 */
		};

		/* node '/soc/timers@40000c00' defined in zephyr/dts/arm/st/f1/stm32f103Xc.dtsi:44 */
		timers5: timers@40000c00 {
			compatible = "st,stm32-timers"; /* in zephyr/dts/arm/st/f1/stm32f103Xc.dtsi:45 */
			reg = < 0x40000c00 0x400 >;     /* in zephyr/dts/arm/st/f1/stm32f103Xc.dtsi:46 */
			clocks = < &rcc 0x1c 0x8 >,
			         < &rcc 0x8 0xff >;     /* in zephyr/dts/arm/st/f1/stm32f103Xc.dtsi:47 */
			resets = < &rctl 0x203 >;       /* in zephyr/dts/arm/st/f1/stm32f103Xc.dtsi:49 */
			interrupts = < 0x32 0x0 >;      /* in zephyr/dts/arm/st/f1/stm32f103Xc.dtsi:50 */
			interrupt-names = "global";     /* in zephyr/dts/arm/st/f1/stm32f103Xc.dtsi:51 */
			st,prescaler = < 0x0 >;         /* in zephyr/dts/arm/st/f1/stm32f103Xc.dtsi:52 */
			status = "disabled";            /* in zephyr/dts/arm/st/f1/stm32f103Xc.dtsi:53 */

			/* node '/soc/timers@40000c00/pwm' defined in zephyr/dts/arm/st/f1/stm32f103Xc.dtsi:55 */
			pwm {
				compatible = "st,stm32-pwm"; /* in zephyr/dts/arm/st/f1/stm32f103Xc.dtsi:56 */
				status = "disabled";         /* in zephyr/dts/arm/st/f1/stm32f103Xc.dtsi:57 */
				#pwm-cells = < 0x3 >;        /* in zephyr/dts/arm/st/f1/stm32f103Xc.dtsi:58 */
			};

			/* node '/soc/timers@40000c00/qdec' defined in zephyr/dts/arm/st/f1/stm32f103Xc.dtsi:61 */
			qdec {
				compatible = "st,stm32-qdec";    /* in zephyr/dts/arm/st/f1/stm32f103Xc.dtsi:62 */
				st,input-filter-level = < 0x0 >; /* in zephyr/dts/arm/st/f1/stm32f103Xc.dtsi:63 */
				status = "disabled";             /* in zephyr/dts/arm/st/f1/stm32f103Xc.dtsi:64 */
			};
		};

		/* node '/soc/timers@40001000' defined in zephyr/dts/arm/st/f1/stm32f103Xc.dtsi:68 */
		timers6: timers@40001000 {
			compatible = "st,stm32-timers"; /* in zephyr/dts/arm/st/f1/stm32f103Xc.dtsi:69 */
			reg = < 0x40001000 0x400 >;     /* in zephyr/dts/arm/st/f1/stm32f103Xc.dtsi:70 */
			clocks = < &rcc 0x1c 0x10 >,
			         < &rcc 0x8 0xff >;     /* in zephyr/dts/arm/st/f1/stm32f103Xc.dtsi:71 */
			resets = < &rctl 0x204 >;       /* in zephyr/dts/arm/st/f1/stm32f103Xc.dtsi:73 */
			interrupts = < 0x36 0x0 >;      /* in zephyr/dts/arm/st/f1/stm32f103Xc.dtsi:74 */
			interrupt-names = "global";     /* in zephyr/dts/arm/st/f1/stm32f103Xc.dtsi:75 */
			st,prescaler = < 0x0 >;         /* in zephyr/dts/arm/st/f1/stm32f103Xc.dtsi:76 */
			status = "disabled";            /* in zephyr/dts/arm/st/f1/stm32f103Xc.dtsi:77 */
		};

		/* node '/soc/timers@40001400' defined in zephyr/dts/arm/st/f1/stm32f103Xc.dtsi:80 */
		timers7: timers@40001400 {
			compatible = "st,stm32-timers"; /* in zephyr/dts/arm/st/f1/stm32f103Xc.dtsi:81 */
			reg = < 0x40001400 0x400 >;     /* in zephyr/dts/arm/st/f1/stm32f103Xc.dtsi:82 */
			clocks = < &rcc 0x1c 0x20 >,
			         < &rcc 0x8 0xff >;     /* in zephyr/dts/arm/st/f1/stm32f103Xc.dtsi:83 */
			resets = < &rctl 0x205 >;       /* in zephyr/dts/arm/st/f1/stm32f103Xc.dtsi:85 */
			interrupts = < 0x37 0x0 >;      /* in zephyr/dts/arm/st/f1/stm32f103Xc.dtsi:86 */
			interrupt-names = "global";     /* in zephyr/dts/arm/st/f1/stm32f103Xc.dtsi:87 */
			st,prescaler = < 0x0 >;         /* in zephyr/dts/arm/st/f1/stm32f103Xc.dtsi:88 */
			status = "disabled";            /* in zephyr/dts/arm/st/f1/stm32f103Xc.dtsi:89 */
		};

		/* node '/soc/spi@40003c00' defined in zephyr/dts/arm/st/f1/stm32f103Xc.dtsi:92 */
		spi3: spi@40003c00 {
			compatible = "st,stm32-spi";   /* in zephyr/dts/arm/st/f1/stm32f103Xc.dtsi:93 */
			#address-cells = < 0x1 >;      /* in zephyr/dts/arm/st/f1/stm32f103Xc.dtsi:94 */
			#size-cells = < 0x0 >;         /* in zephyr/dts/arm/st/f1/stm32f103Xc.dtsi:95 */
			reg = < 0x40003c00 0x400 >;    /* in zephyr/dts/arm/st/f1/stm32f103Xc.dtsi:96 */
			clocks = < &rcc 0x1c 0x8000 >; /* in zephyr/dts/arm/st/f1/stm32f103Xc.dtsi:97 */
			interrupts = < 0x33 0x5 >;     /* in zephyr/dts/arm/st/f1/stm32f103Xc.dtsi:98 */
			status = "disabled";           /* in zephyr/dts/arm/st/f1/stm32f103Xc.dtsi:99 */
		};

		/* node '/soc/dac@40007400' defined in zephyr/dts/arm/st/f1/stm32f103Xc.dtsi:102 */
		dac1: dac@40007400 {
			compatible = "st,stm32-dac";       /* in zephyr/dts/arm/st/f1/stm32f103Xc.dtsi:103 */
			reg = < 0x40007400 0x400 >;        /* in zephyr/dts/arm/st/f1/stm32f103Xc.dtsi:104 */
			clocks = < &rcc 0x1c 0x20000000 >; /* in zephyr/dts/arm/st/f1/stm32f103Xc.dtsi:105 */
			status = "disabled";               /* in zephyr/dts/arm/st/f1/stm32f103Xc.dtsi:106 */
			#io-channel-cells = < 0x1 >;       /* in zephyr/dts/arm/st/f1/stm32f103Xc.dtsi:107 */
		};

		/* node '/soc/adc@40012800' defined in zephyr/dts/arm/st/f1/stm32f103Xc.dtsi:130 */
		adc2: adc@40012800 {
			compatible = "st,stm32-adc";                               /* in zephyr/dts/arm/st/f1/stm32f103Xc.dtsi:131 */
			reg = < 0x40012800 0x400 >;                                /* in zephyr/dts/arm/st/f1/stm32f103Xc.dtsi:132 */
			clocks = < &rcc 0x18 0x400 >;                              /* in zephyr/dts/arm/st/f1/stm32f103Xc.dtsi:133 */
			clock-names = "adcx";                                      /* in zephyr/dts/arm/st/f1/stm32f103Xc.dtsi:134 */
			interrupts = < 0x12 0x0 >;                                 /* in zephyr/dts/arm/st/f1/stm32f103Xc.dtsi:136 */
			#io-channel-cells = < 0x1 >;                               /* in zephyr/dts/arm/st/f1/stm32f103Xc.dtsi:137 */
			resolutions = < 0x6000ff >;                                /* in zephyr/dts/arm/st/f1/stm32f103Xc.dtsi:138 */
			sampling-times = < 0x2 0x8 0xe 0x1d 0x2a 0x38 0x48 0xf0 >; /* in zephyr/dts/arm/st/f1/stm32f103Xc.dtsi:139 */
			st,adc-sequencer = "programmable";                         /* in zephyr/dts/arm/st/f1/stm32f103Xc.dtsi:140 */
			st,adc-oversampler = "none";                               /* in zephyr/dts/arm/st/f1/stm32f103Xc.dtsi:141 */
			st,adc-internal-regulator = "none";                        /* in zephyr/dts/arm/st/f1/stm32f103Xc.dtsi:142 */
			status = "disabled";                                       /* in zephyr/dts/arm/st/f1/stm32f103Xc.dtsi:143 */
		};

		/* node '/soc/adc@40013c00' defined in zephyr/dts/arm/st/f1/stm32f103Xc.dtsi:146 */
		adc3: adc@40013c00 {
			compatible = "st,stm32-adc";                               /* in zephyr/dts/arm/st/f1/stm32f103Xc.dtsi:147 */
			reg = < 0x40013c00 0x400 >;                                /* in zephyr/dts/arm/st/f1/stm32f103Xc.dtsi:148 */
			clocks = < &rcc 0x18 0x8000 >;                             /* in zephyr/dts/arm/st/f1/stm32f103Xc.dtsi:149 */
			clock-names = "adcx";                                      /* in zephyr/dts/arm/st/f1/stm32f103Xc.dtsi:150 */
			interrupts = < 0x2f 0x0 >;                                 /* in zephyr/dts/arm/st/f1/stm32f103Xc.dtsi:151 */
			#io-channel-cells = < 0x1 >;                               /* in zephyr/dts/arm/st/f1/stm32f103Xc.dtsi:152 */
			resolutions = < 0x6000ff >;                                /* in zephyr/dts/arm/st/f1/stm32f103Xc.dtsi:153 */
			sampling-times = < 0x2 0x8 0xe 0x1d 0x2a 0x38 0x48 0xf0 >; /* in zephyr/dts/arm/st/f1/stm32f103Xc.dtsi:154 */
			st,adc-sequencer = "programmable";                         /* in zephyr/dts/arm/st/f1/stm32f103Xc.dtsi:155 */
			st,adc-oversampler = "none";                               /* in zephyr/dts/arm/st/f1/stm32f103Xc.dtsi:156 */
			st,adc-internal-regulator = "none";                        /* in zephyr/dts/arm/st/f1/stm32f103Xc.dtsi:157 */
			status = "disabled";                                       /* in zephyr/dts/arm/st/f1/stm32f103Xc.dtsi:158 */
		};

		/* node '/soc/timers@40013400' defined in zephyr/dts/arm/st/f1/stm32f103Xc.dtsi:161 */
		timers8: timers@40013400 {
			compatible = "st,stm32-timers"; /* in zephyr/dts/arm/st/f1/stm32f103Xc.dtsi:162 */
			reg = < 0x40013400 0x400 >;     /* in zephyr/dts/arm/st/f1/stm32f103Xc.dtsi:163 */
			clocks = < &rcc 0x18 0x2000 >;  /* in zephyr/dts/arm/st/f1/stm32f103Xc.dtsi:164 */
			resets = < &rctl 0x18d >;       /* in zephyr/dts/arm/st/f1/stm32f103Xc.dtsi:165 */
			interrupts = < 0x2b 0x0 >,
			             < 0x2c 0x0 >,
			             < 0x2d 0x0 >,
			             < 0x2e 0x0 >;      /* in zephyr/dts/arm/st/f1/stm32f103Xc.dtsi:166 */
			interrupt-names = "brk",
			                  "up",
			                  "trgcom",
			                  "cc";         /* in zephyr/dts/arm/st/f1/stm32f103Xc.dtsi:167 */
			st,prescaler = < 0x0 >;         /* in zephyr/dts/arm/st/f1/stm32f103Xc.dtsi:168 */
			status = "disabled";            /* in zephyr/dts/arm/st/f1/stm32f103Xc.dtsi:169 */

			/* node '/soc/timers@40013400/pwm' defined in zephyr/dts/arm/st/f1/stm32f103Xc.dtsi:171 */
			pwm {
				compatible = "st,stm32-pwm"; /* in zephyr/dts/arm/st/f1/stm32f103Xc.dtsi:172 */
				status = "disabled";         /* in zephyr/dts/arm/st/f1/stm32f103Xc.dtsi:173 */
				#pwm-cells = < 0x3 >;        /* in zephyr/dts/arm/st/f1/stm32f103Xc.dtsi:174 */
			};
		};

		/* node '/soc/dma@40020400' defined in zephyr/dts/arm/st/f1/stm32f103Xc.dtsi:178 */
		dma2: dma@40020400 {
			compatible = "st,stm32-dma-v2bis";                             /* in zephyr/dts/arm/st/f1/stm32f103Xc.dtsi:179 */
			#dma-cells = < 0x2 >;                                          /* in zephyr/dts/arm/st/f1/stm32f103Xc.dtsi:180 */
			reg = < 0x40020400 0x400 >;                                    /* in zephyr/dts/arm/st/f1/stm32f103Xc.dtsi:181 */
			clocks = < &rcc 0x14 0x2 >;                                    /* in zephyr/dts/arm/st/f1/stm32f103Xc.dtsi:182 */
			interrupts = < 0x38 0x0 0x39 0x0 0x3a 0x0 0x3b 0x0 0x3c 0x0 >; /* in zephyr/dts/arm/st/f1/stm32f103Xc.dtsi:183 */
			status = "disabled";                                           /* in zephyr/dts/arm/st/f1/stm32f103Xc.dtsi:184 */
		};
	};

	/* node '/cpus' defined in zephyr/dts/arm/st/f1/stm32f1.dtsi:29 */
	cpus {
		#address-cells = < 0x1 >; /* in zephyr/dts/arm/st/f1/stm32f1.dtsi:30 */
		#size-cells = < 0x0 >;    /* in zephyr/dts/arm/st/f1/stm32f1.dtsi:31 */

		/* node '/cpus/cpu@0' defined in zephyr/dts/arm/st/f1/stm32f1.dtsi:33 */
		cpu0: cpu@0 {
			device_type = "cpu";                  /* in zephyr/dts/arm/st/f1/stm32f1.dtsi:34 */
			compatible = "arm,cortex-m3";         /* in zephyr/dts/arm/st/f1/stm32f1.dtsi:35 */
			cpu-power-states = < &stop0 &stop1 >; /* in zephyr/dts/arm/st/f1/stm32f1.dtsi:36 */
			reg = < 0x0 >;                        /* in zephyr/dts/arm/st/f1/stm32f1.dtsi:37 */
		};

		/* node '/cpus/power-states' defined in zephyr/dts/arm/st/f1/stm32f1.dtsi:40 */
		power-states {

			/* node '/cpus/power-states/stop0' defined in zephyr/dts/arm/st/f1/stm32f1.dtsi:41 */
			stop0: stop0 {
				compatible = "zephyr,power-state";    /* in zephyr/dts/arm/st/f1/stm32f1.dtsi:42 */
				power-state-name = "suspend-to-idle"; /* in zephyr/dts/arm/st/f1/stm32f1.dtsi:43 */
				substate-id = < 0x0 >;                /* in zephyr/dts/arm/st/f1/stm32f1.dtsi:44 */
				min-residency-us = < 0xf4240 >;       /* in zephyr/dts/arm/st/f1/stm32f1.dtsi:45 */
				exit-latency-us = < 0x190 >;          /* in zephyr/dts/arm/st/f1/stm32f1.dtsi:46 */
				phandle = < 0x1a >;                   /* in zephyr/dts/arm/st/f1/stm32f1.dtsi:36 */
			};

			/* node '/cpus/power-states/stop1' defined in zephyr/dts/arm/st/f1/stm32f1.dtsi:49 */
			stop1: stop1 {
				compatible = "zephyr,power-state";    /* in zephyr/dts/arm/st/f1/stm32f1.dtsi:50 */
				power-state-name = "suspend-to-idle"; /* in zephyr/dts/arm/st/f1/stm32f1.dtsi:51 */
				substate-id = < 0x1 >;                /* in zephyr/dts/arm/st/f1/stm32f1.dtsi:52 */
				min-residency-us = < 0xf4240 >;       /* in zephyr/dts/arm/st/f1/stm32f1.dtsi:53 */
				exit-latency-us = < 0x258 >;          /* in zephyr/dts/arm/st/f1/stm32f1.dtsi:54 */
				phandle = < 0x1b >;                   /* in zephyr/dts/arm/st/f1/stm32f1.dtsi:36 */
			};
		};
	};

	/* node '/memory@20000000' defined in zephyr/dts/arm/st/f1/stm32f1.dtsi:59 */
	sram0: memory@20000000 {
		compatible = "zephyr,memory-region",
		             "mmio-sram";            /* in zephyr/dts/arm/st/f1/stm32f1.dtsi:60 */
		zephyr,memory-region = "SRAM0";      /* in zephyr/dts/arm/st/f1/stm32f1.dtsi:61 */
		reg = < 0x20000000 0xc000 >;         /* in zephyr/dts/arm/st/f1/stm32f103Xc.dtsi:15 */
	};

	/* node '/clocks' defined in zephyr/dts/arm/st/f1/stm32f1.dtsi:64 */
	clocks {

		/* node '/clocks/clk-hse' defined in zephyr/dts/arm/st/f1/stm32f1.dtsi:65 */
		clk_hse: clk-hse {
			#clock-cells = < 0x0 >;            /* in zephyr/dts/arm/st/f1/stm32f1.dtsi:66 */
			compatible = "st,stm32-hse-clock"; /* in zephyr/dts/arm/st/f1/stm32f1.dtsi:67 */
			clock-frequency = < 0x7a1200 >;    /* in zephyr/boards/others/stm32f103_mini/stm32f103_mini.dts:43 */
			status = "okay";                   /* in zephyr/boards/others/stm32f103_mini/stm32f103_mini.dts:44 */
			phandle = < 0x1c >;                /* in zephyr/boards/others/stm32f103_mini/stm32f103_mini.dts:49 */
		};

		/* node '/clocks/clk-hsi' defined in zephyr/dts/arm/st/f1/stm32f1.dtsi:71 */
		clk_hsi: clk-hsi {
			#clock-cells = < 0x0 >;         /* in zephyr/dts/arm/st/f1/stm32f1.dtsi:72 */
			compatible = "fixed-clock";     /* in zephyr/dts/arm/st/f1/stm32f1.dtsi:73 */
			clock-frequency = < 0x7a1200 >; /* in zephyr/dts/arm/st/f1/stm32f1.dtsi:74 */
			status = "disabled";            /* in zephyr/dts/arm/st/f1/stm32f1.dtsi:75 */
		};

		/* node '/clocks/clk-lse' defined in zephyr/dts/arm/st/f1/stm32f1.dtsi:78 */
		clk_lse: clk-lse {
			#clock-cells = < 0x0 >;       /* in zephyr/dts/arm/st/f1/stm32f1.dtsi:79 */
			compatible = "fixed-clock";   /* in zephyr/dts/arm/st/f1/stm32f1.dtsi:80 */
			clock-frequency = < 0x8000 >; /* in zephyr/dts/arm/st/f1/stm32f1.dtsi:81 */
			status = "disabled";          /* in zephyr/dts/arm/st/f1/stm32f1.dtsi:82 */
		};

		/* node '/clocks/clk-lsi' defined in zephyr/dts/arm/st/f1/stm32f1.dtsi:85 */
		clk_lsi: clk-lsi {
			#clock-cells = < 0x0 >;       /* in zephyr/dts/arm/st/f1/stm32f1.dtsi:86 */
			compatible = "fixed-clock";   /* in zephyr/dts/arm/st/f1/stm32f1.dtsi:87 */
			clock-frequency = < 0x9c40 >; /* in zephyr/dts/arm/st/f1/stm32f1.dtsi:88 */
			status = "okay";              /* in zephyr/boards/others/stm32f103_mini/stm32f103_mini.dts:39 */
		};

		/* node '/clocks/pll' defined in zephyr/dts/arm/st/f1/stm32f1.dtsi:92 */
		pll: pll {
			#clock-cells = < 0x0 >;              /* in zephyr/dts/arm/st/f1/stm32f1.dtsi:93 */
			compatible = "st,stm32f1-pll-clock"; /* in zephyr/dts/arm/st/f1/stm32f1.dtsi:94 */
			mul = < 0x9 >;                       /* in zephyr/boards/others/stm32f103_mini/stm32f103_mini.dts:48 */
			clocks = < &clk_hse >;               /* in zephyr/boards/others/stm32f103_mini/stm32f103_mini.dts:49 */
			status = "okay";                     /* in zephyr/boards/others/stm32f103_mini/stm32f103_mini.dts:50 */
			phandle = < 0x3 >;                   /* in zephyr/boards/others/stm32f103_mini/stm32f103_mini.dts:54 */
		};
	};

	/* node '/mcos' defined in zephyr/dts/arm/st/f1/stm32f1.dtsi:99 */
	mcos {

		/* node '/mcos/mco1' defined in zephyr/dts/arm/st/f1/stm32f1.dtsi:100 */
		mco1: mco1 {
			compatible = "st,stm32f1-clock-mco"; /* in zephyr/dts/arm/st/f1/stm32f1.dtsi:101 */
			status = "disabled";                 /* in zephyr/dts/arm/st/f1/stm32f1.dtsi:102 */
		};
	};

	/* node '/power@40007000' defined in zephyr/dts/arm/st/f1/stm32f1.dtsi:418 */
	pwr: power@40007000 {
		compatible = "st,stm32-pwr"; /* in zephyr/dts/arm/st/f1/stm32f1.dtsi:419 */
		reg = < 0x40007000 0x400 >;  /* in zephyr/dts/arm/st/f1/stm32f1.dtsi:420 */
		status = "disabled";         /* in zephyr/dts/arm/st/f1/stm32f1.dtsi:421 */
		wkup-pins-nb = < 0x1 >;      /* in zephyr/dts/arm/st/f1/stm32f1.dtsi:423 */
		#address-cells = < 0x1 >;    /* in zephyr/dts/arm/st/f1/stm32f1.dtsi:425 */
		#size-cells = < 0x0 >;       /* in zephyr/dts/arm/st/f1/stm32f1.dtsi:426 */

		/* node '/power@40007000/wkup-pin@1' defined in zephyr/dts/arm/st/f1/stm32f1.dtsi:428 */
		wkup-pin@1 {
			reg = < 0x1 >;                   /* in zephyr/dts/arm/st/f1/stm32f1.dtsi:429 */
			wkup-gpios = < &gpioa 0x0 0x1 >; /* in zephyr/dts/arm/st/f1/stm32f1.dtsi:430 */
		};
	};

	/* node '/dietemp' defined in zephyr/dts/arm/st/f1/stm32f1.dtsi:434 */
	die_temp: dietemp {
		compatible = "st,stm32-temp"; /* in zephyr/dts/arm/st/f1/stm32f1.dtsi:435 */
		io-channels = < &adc1 0x10 >; /* in zephyr/dts/arm/st/f1/stm32f1.dtsi:436 */
		avgslope = "4.3";             /* in zephyr/dts/arm/st/f1/stm32f1.dtsi:438 */
		v25 = < 0x596 >;              /* in zephyr/dts/arm/st/f1/stm32f1.dtsi:439 */
		ntc;                          /* in zephyr/dts/arm/st/f1/stm32f1.dtsi:440 */
		status = "okay";              /* in zephyr/boards/others/stm32f103_mini/stm32f103_mini.dts:136 */
	};

	/* node '/smbus1' defined in zephyr/dts/arm/st/f1/stm32f1.dtsi:443 */
	smbus1: smbus1 {
		compatible = "st,stm32-smbus"; /* in zephyr/dts/arm/st/f1/stm32f1.dtsi:444 */
		#address-cells = < 0x1 >;      /* in zephyr/dts/arm/st/f1/stm32f1.dtsi:445 */
		#size-cells = < 0x0 >;         /* in zephyr/dts/arm/st/f1/stm32f1.dtsi:446 */
		i2c = < &i2c1 >;               /* in zephyr/dts/arm/st/f1/stm32f1.dtsi:447 */
		status = "disabled";           /* in zephyr/dts/arm/st/f1/stm32f1.dtsi:448 */
	};

	/* node '/smbus2' defined in zephyr/dts/arm/st/f1/stm32f1.dtsi:451 */
	smbus2: smbus2 {
		compatible = "st,stm32-smbus"; /* in zephyr/dts/arm/st/f1/stm32f1.dtsi:452 */
		#address-cells = < 0x1 >;      /* in zephyr/dts/arm/st/f1/stm32f1.dtsi:453 */
		#size-cells = < 0x0 >;         /* in zephyr/dts/arm/st/f1/stm32f1.dtsi:454 */
		i2c = < &i2c2 >;               /* in zephyr/dts/arm/st/f1/stm32f1.dtsi:455 */
		status = "disabled";           /* in zephyr/dts/arm/st/f1/stm32f1.dtsi:456 */
	};

	/* node '/usbphy' defined in zephyr/dts/arm/st/f1/stm32f103X8.dtsi:60 */
	usb_fs_phy: usbphy {
		compatible = "usb-nop-xceiv"; /* in zephyr/dts/arm/st/f1/stm32f103X8.dtsi:61 */
		#phy-cells = < 0x0 >;         /* in zephyr/dts/arm/st/f1/stm32f103X8.dtsi:62 */
		phandle = < 0x17 >;           /* in zephyr/dts/arm/st/f1/stm32f103X8.dtsi:47 */
	};

	/* node '/leds' defined in zephyr/boards/others/stm32f103_mini/stm32f103_mini.dts:22 */
	leds {
		compatible = "gpio-leds"; /* in zephyr/boards/others/stm32f103_mini/stm32f103_mini.dts:23 */

		/* node '/leds/led_1' defined in zephyr/boards/others/stm32f103_mini/stm32f103_mini.dts:25 */
		green_led_1: led_1 {
			gpios = < &gpioc 0xd 0x1 >; /* in zephyr/boards/others/stm32f103_mini/stm32f103_mini.dts:26 */
			label = "User LD1";         /* in zephyr/boards/others/stm32f103_mini/stm32f103_mini.dts:27 */
		};
	};
};
